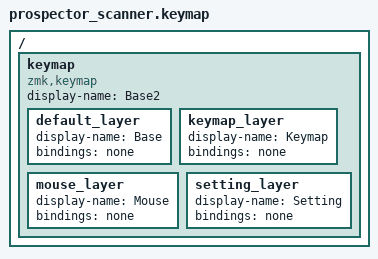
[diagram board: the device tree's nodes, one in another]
/*
 * Copyright (c) 2024 The ZMK Contributors
 *
 * SPDX-License-Identifier: MIT
 */

#include <behaviors.dtsi>
#include <dt-bindings/zmk/keys.h>
#include <dt-bindings/zmk/bt.h>
#include <dt-bindings/zmk/outputs.h>

/*
 * Layer names are read locally by the YADS2 layout through ZMK's
 * zmk_keymap_layer_name(), so full display-names can be used here.
 * (Only layouts that show the name *received over the status advertisement* are
 * limited to 4 characters - struct zmk_status_adv_data.layer_name[4].)
 */
/ {
    keymap {
        compatible = "zmk,keymap";
        display-name = "Base2";
        // Default layer - scanner has no physical keys
        default_layer {
            display-name = "Base";
            bindings = <&none>;
        };

        keymap_layer {
            display-name = "Keymap";
            bindings = <&none>;
        };

        mouse_layer {
            display-name = "Mouse";
            bindings = <&none>;
        };

        setting_layer {
            display-name = "Setting";
            bindings = <&none>;
        };
    };
};

// Touch input - direct CST816S handling for raw coordinate debugging
